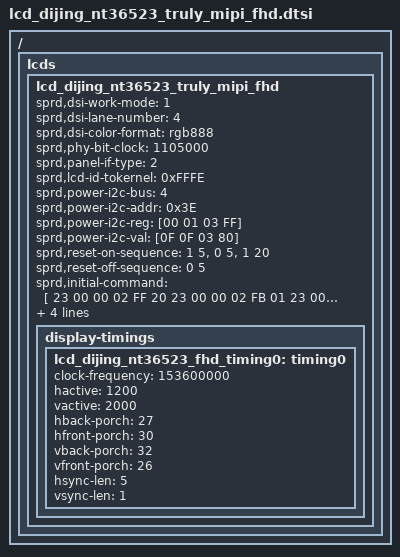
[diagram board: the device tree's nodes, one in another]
/*
 * dijing_2A4N3 Truly LCD config dtsi file for spreadtrum
 *
 * Copyright (C) 2018, Spreadtrum Communications Inc.
 *
 * SPDX-License-Identifier: (GPL-2.0+ OR MIT)
 */

/ { lcds {
	lcd_dijing_nt36523_truly_mipi_fhd: lcd_dijing_nt36523_truly_mipi_fhd {

					sprd,dsi-work-mode = <1>; /* video burst mode*/
					sprd,dsi-lane-number = <4>;
					sprd,dsi-color-format = "rgb888";

					sprd,phy-bit-clock = <1105000>;	/* 1062000~1075000 kbps 1068000 */

		/* panel interface type: 2:MIPI; 3:SPI */
		sprd,panel-if-type = <2>;

		/*----Id register ----*/
	//	sprd,lcd-id-register = [DA DB DC];
	//	sprd,lcd-id-value-len = <1 1 1>;
	//	sprd,lcd-id-value = [00 80 00];
		sprd,lcd-id-tokernel = <0xFFFE>;

		/*---Bias Power---*/
		sprd,power-i2c-bus = <4>;
		sprd,power-i2c-addr = <0x3E>;
		/*sprd,power-i2c-speed = <400000>;*/
		sprd,power-i2c-reg = [00 01 03 FF];
		sprd,power-i2c-val = [0F 0F 03 80];
		sprd,reset-on-sequence = <1 5>, <0 5>, <1 20>;
		sprd,reset-off-sequence = <0 5>;

		sprd,initial-command = [
				23 00 00 02 FF 20
				23 00 00 02 FB 01
				23 00 00 02 05 B1
				23 00 00 02 06 C0
				23 00 00 02 07 73
				23 00 00 02 08 4B
				23 00 00 02 0D 23
				23 00 00 02 0E 89
				23 00 00 02 0F 69
			//	23 00 00 02 88 00
			//	23 00 00 02 89 59
				23 00 00 02 94 00
				23 00 00 02 95 C3
                                23 00 00 02 96 C3
				23 00 00 02 09 99
				23 00 00 02 0A 88
				23 00 00 02 0B 10
				23 00 00 02 0C 00
				23 00 00 02 10 0C
				23 00 00 02 33 11
				23 00 00 02 58 60
				23 00 00 02 60 88
				23 00 00 02 30 10
				23 00 00 02 31 02
				23 00 00 02 32 B2
				//Chopper
				23 00 00 02 75 A2
				23 00 00 02 77 66
				
				//GAMMA
				23 00 00 02 FF 20
				23 00 00 02 FB 01
				//R(+)
				39 00 00 11 B0 00 08 00 28 00 57 00 7B 00 99 00 B2 00 C8 00 DC
				39 00 00 11 B1 00 EC 01 26 01 4C 01 8B 01 B6 01 FA 02 2B 02 2D
				39 00 00 11 B2 02 5E 02 98 02 C8 02 FE 03 28 03 56 03 68 03 78
				39 00 00 0D B3 03 8B 03 A0 03 B5 03 E4 03 FD 03 FF
				//G(+)
				39 00 00 11 B4 00 08 00 28 00 57 00 7B 00 99 00 B2 00 C8 00 DC
				39 00 00 11 B5 00 EC 01 26 01 4C 01 8B 01 B6 01 FA 02 2B 02 2D
				39 00 00 11 B6 02 5E 02 98 02 C8 02 FE 03 28 03 56 03 68 03 78
				39 00 00 0D B7 03 8B 03 A0 03 B5 03 E4 03 FD 03 FF
				//B(+)
				39 00 00 11 B8 00 08 00 28 00 57 00 7B 00 99 00 B2 00 C8 00 DC
				39 00 00 11 B9 00 EC 01 26 01 4C 01 8B 01 B6 01 FA 02 2B 02 2D
				39 00 00 11 BA 02 5E 02 98 02 C8 02 FE 03 28 03 56 03 68 03 78
				39 00 00 0D BB 03 8B 03 A0 03 B5 03 E4 03 FD 03 FF
				
				23 00 00 02 FF 21
				23 00 00 02 FB 01
				//R(-)
				39 00 00 11 B0 00 00 00 20 00 4F 00 73 00 91 00 AA 00 C0 00 D4
				39 00 00 11 B1 00 E4 01 1E 01 44 01 83 01 AE 01 F2 02 23 02 25
				39 00 00 11 B2 02 56 02 90 02 C0 02 F6 03 20 03 4E 03 60 03 70
				39 00 00 0D B3 03 83 03 98 03 AD 03 DC 03 F5 03 F7
				//G(-)
				39 00 00 11 B4 00 00 00 20 00 4F 00 73 00 91 00 AA 00 C0 00 D4
				39 00 00 11 B5 00 E4 01 1E 01 44 01 83 01 AE 01 F2 02 23 02 25
				39 00 00 11 B6 02 56 02 90 02 C0 02 F6 03 20 03 4E 03 60 03 70
				39 00 00 0D B7 03 83 03 98 03 AD 03 DC 03 F5 03 F7
				//B(-)
				39 00 00 11 B8 00 00 00 20 00 4F 00 73 00 91 00 AA 00 C0 00 D4
				39 00 00 11 B9 00 E4 01 1E 01 44 01 83 01 AE 01 F2 02 23 02 25
				39 00 00 11 BA 02 56 02 90 02 C0 02 F6 03 20 03 4E 03 60 03 70
				39 00 00 0D BB 03 83 03 98 03 AD 03 DC 03 F5 03 F7
				
				23 00 00 02 FF 23
				23 00 00 02 FB 01
				23 00 00 02 00 80
				23 00 00 02 07 00
				23 00 00 02 08 01
				23 00 00 02 09 2C
				23 00 00 02 11 01
				23 00 00 02 12 77
				23 00 00 02 15 07
				23 00 00 02 16 07
				
				23 00 00 02 FF 24
				23 00 00 02 FB 01
				23 00 00 02 60 96
				23 00 00 02 61 D0
				23 00 00 02 63 70
				23 00 00 02 91 00
				23 00 00 02 92 D4
				23 00 00 02 93 1A
				23 00 00 02 94 08
				23 00 00 02 C2 CA
				23 00 00 02 00 29
				23 00 00 02 01 08
				23 00 00 02 02 28
				23 00 00 02 03 03
				23 00 00 02 04 04
				23 00 00 02 05 13
				23 00 00 02 06 12
				23 00 00 02 07 11
				23 00 00 02 08 10
				23 00 00 02 09 0F
				23 00 00 02 0A 0E
				23 00 00 02 0B 0D
				23 00 00 02 0C 0C
				23 00 00 02 0D 27
				23 00 00 02 0E 03
				23 00 00 02 0F 03
				23 00 00 02 10 03
				23 00 00 02 11 03
				23 00 00 02 12 03
				23 00 00 02 13 03
				23 00 00 02 14 03
				23 00 00 02 15 03
				23 00 00 02 16 29
				23 00 00 02 17 08
				23 00 00 02 18 28
				23 00 00 02 19 03
				23 00 00 02 1A 04
				23 00 00 02 1B 13
				23 00 00 02 1C 12
				23 00 00 02 1D 11
				23 00 00 02 1E 10
				23 00 00 02 1F 0F
				23 00 00 02 20 0E
				23 00 00 02 21 0D
				23 00 00 02 22 0C
				23 00 00 02 23 27
				23 00 00 02 24 03
				23 00 00 02 25 03
				23 00 00 02 26 03
				23 00 00 02 27 03
				23 00 00 02 28 03
				23 00 00 02 29 03
				23 00 00 02 2A 03
				23 00 00 02 2B 03
				23 00 00 02 2F 06
				23 00 00 02 33 06
				23 00 00 02 37 44
				23 00 00 02 3A 02
				23 00 00 02 3B 98
				23 00 00 02 3D 81
				23 00 00 02 AB 44
				23 00 00 02 3F 5B
				23 00 00 02 43 5B
				23 00 00 02 47 44
				23 00 00 02 4A 02
				23 00 00 02 4B 68
				23 00 00 02 4C 01
				23 00 00 02 F7 44
				23 00 00 02 4D 21                                                                                                                         
				23 00 00 02 4E 43                                                                                                                          
				23 00 00 02 4F 65                                                                                                                          
				23 00 00 02 50 87                                                                                                                          
				23 00 00 02 51 78                                                                                                                          
				23 00 00 02 52 56                                                                                                                          
				23 00 00 02 53 34                                                                                                                          
				23 00 00 02 54 12                                                                                                                          
				39 00 00 03 55 85 05                                                                                                                     
				23 00 00 02 56 08                                                                                                                          
				23 00 00 02 58 10                                                                                                                          
				23 00 00 02 59 20                                                                                                                          
				23 00 00 02 5A A0                                                                                                                          
				23 00 00 02 5B 98                                                                                                                          
				23 00 00 02 5C 00                                                                                                                          
				23 00 00 02 5D 00                                                                                                                          
				39 00 00 03 5E 00 04                                                                                                                       
				23 00 00 02 5F 00                                                                                                                          
				23 00 00 02 98 80                                                                                                                          
				23 00 00 02 AA 03                                                                                                                          
				23 00 00 02 D7 55                                                                                                                          
				23 00 00 02 D8 55                                                                                                                          
				23 00 00 02 D9 23                                                                                                                          
				23 00 00 02 DA 05                                                                                                                          
				23 00 00 02 DB 72                                                                                                                          
				23 00 00 02 DC D0                                                                                                                          
				23 00 00 02 DD 55                                                                                                                          
				23 00 00 02 DE 27                                                                                                                          
				23 00 00 02 DF 02                                                                                                                          
				23 00 00 02 E0 D0                                                                                                                          
				23 00 00 02 E1 02                                                                                                                          
				23 00 00 02 E2 D0                                                                                                                          
				23 00 00 02 E3 02                                                                                                                          
				23 00 00 02 E4 D0                                                                                                                          
				23 00 00 02 E5 02                                                                                                                          
				23 00 00 02 E6 D0                                                                                                                          
				23 00 00 02 E7 00                                                                                                                          
				23 00 00 02 E8 00                                                                                                                          
				23 00 00 02 E9 02                                                                                                                          
				23 00 00 02 EA D0                                                                                                                          
				23 00 00 02 EB 02                                                                                                                          
				23 00 00 02 EE D0                                                                                                                          
				23 00 00 02 EF 02                                                                                                                          
				23 00 00 02 F0 D0
				39 00 00 0D B6 05 00 05 00 00 00 00 00 05 05 00 00
				
				23 00 00 02 FF 25				
				23 00 00 02 FB 01                                                                                                                          
				23 00 00 02 05 00                                                                                                                          
				23 00 00 02 13 03                                                                                                                          
				23 00 00 02 14 12                                                                                                                          
				23 00 00 02 19 07                                                                                                                          
				23 00 00 02 1B 11                                                                                                                          
				23 00 00 02 1E 00                                                                                                                          
				23 00 00 02 1F A0                                                                                                                          
				23 00 00 02 20 98                                                                                                                          
				23 00 00 02 25 00                                                                                                                          
				23 00 00 02 26 A0                                                                                                                          
				23 00 00 02 27 98                                                                                                                          
				23 00 00 02 3F 00                                                                                                                          
				23 00 00 02 40 03                                                                                                                          
				23 00 00 02 43 00                                                                                                                          
				23 00 00 02 48 A0                                                                                                                          
				23 00 00 02 49 98                                                                                                                          
				23 00 00 02 44 02                                                                                                                          
				23 00 00 02 45 98                                                                                                                          
				23 00 00 02 46 02                                                                                                                          
				23 00 00 02 47 98                                                                                                                          
				23 00 00 02 5D 02                                                                                                                          
				23 00 00 02 5E 98                                                                                                                          
				23 00 00 02 5F 02                                                                                                                          
				23 00 00 02 60 98                                                                                                                          
				23 00 00 02 61 A0                                                                                                                          
				23 00 00 02 62 98                                                                                                                          
				23 00 00 02 6B 40                                                                                                                          
				23 00 00 02 6C 0D                                                                                                                          
				23 00 00 02 6D 0D                                                                                                                          
				23 00 00 02 6E 0E                                                                                                                          
				23 00 00 02 6F 0E                                                                                                                          
				23 00 00 02 78 00                                                                                                                          
				23 00 00 02 79 DA                                                                                                                          
				23 00 00 02 7A 00                                                                                                                          
				23 00 00 02 7B 68                                                                                                                          
				23 00 00 02 86 01                                                                                                                          
				23 00 00 02 87 0A                                                                                                                          
				23 00 00 02 88 1A                                                                                                                          
				23 00 00 02 C0 0C 
				
				23 00 00 02 FF 26			
				23 00 00 02 FB 01                                                                                                                          
				23 00 00 02 00 A1                                                                                                                          
				23 00 00 02 04 28                                                                                                                          
				23 00 00 02 06 30                                                                                                                          
				23 00 00 02 0C 11                                                                                                                          
				23 00 00 02 0D 00                                                                                                                          
				23 00 00 02 0F 09                                                                                                                          
				23 00 00 02 11 12                                                                                                                          
				23 00 00 02 12 50                                                                                                                          
				23 00 00 02 13 6D                                                                                                                          
				23 00 00 02 14 93                                                                                                                          
				23 00 00 02 15 00                                                                                                                          
				23 00 00 02 16 90                                                                                                                          
				23 00 00 02 17 A0                                                                                                                          
				23 00 00 02 18 86                                                                                                                          
				23 00 00 02 19 11                                                                                                                          
				23 00 00 02 1A 00                                                                                                                          
				23 00 00 02 1B 0E                                                                                                                          
				23 00 00 02 1C DC                                                                                                                          
				23 00 00 02 22 00                                                                                                                          
				23 00 00 02 23 00                                                                                                                          
				23 00 00 02 2A 11                                                                                                                          
				23 00 00 02 2B 00                                                                                                                          
				23 00 00 02 1D 00                                                                                                                          
				23 00 00 02 1E D4                                                                                                                          
				23 00 00 02 1F D4                                                                                                                          
				23 00 00 02 20 00                                                                                                                          
				23 00 00 02 21 07                                                                                                                          
				23 00 00 02 2F 03                                                                                                                          
				23 00 00 02 30 D4                                                                                                                          
				23 00 00 02 33 78                                                                                                                          
				23 00 00 02 34 16                                                                                                                          
				23 00 00 02 35 11                                                                                                                          
				23 00 00 02 39 04                                                                                                                          
				23 00 00 02 3A D4                                                                                                                          
				23 00 00 02 3B 06                                                                                                                          
				23 00 00 02 3F 00                                                                                                                          
				23 00 00 02 40 C8                                                                                                                          
				23 00 00 02 41 C8                                                                                                                          
				23 00 00 02 42 C8                                                                                                                          
				23 00 00 02 43 01                                                                                                                          
				23 00 00 02 44 C8                                                                                                                          
				23 00 00 02 45 05                                                                                                                          
				23 00 00 02 46 C8                                                                                                                          
				23 00 00 02 47 00                                                                                                                          
				23 00 00 02 48 C8                                                                                                                          
				23 00 00 02 49 05                                                                                                                          
				23 00 00 02 4A C8                                                                                                                          
				23 00 00 02 4B 80                                                                                                                          
				23 00 00 02 8B 28                                                                                                                          
				23 00 00 02 8C 00                                                                                                                          
				23 00 00 02 8D 01                                                                                                                          
				23 00 00 02 8F 01                                                                                                                          
				23 00 00 02 91 00                                                                                                                          
				23 00 00 02 92 50                                                                                                                          
				23 00 00 02 93 00                                                                                                                          
				23 00 00 02 94 00                                                                                                                          
				23 00 00 02 95 00                                                                                                                          
				23 00 00 02 96 00                                                                                                                          
				23 00 00 02 97 A0                                                                                                                          
				23 00 00 02 98 86                                                                                                                          
				23 00 00 02 99 0F                                                                                                                          
				23 00 00 02 9A 9C                                                                                                                          
				23 00 00 02 9B 0E                                                                                                                          
				23 00 00 02 9C DC                                                                                                                          
				23 00 00 02 9D 0F                                                                                                                          
				23 00 00 02 9E 9C                                                                                                                          
				23 00 00 02 9F 00                                                                                                                          
				23 00 00 02 A0 00                                                                                                                          
				23 00 00 02 C8 04                                                                                                                          
				23 00 00 02 C9 12                                                                                                                          
				23 00 00 02 CA 4E                                                                                                                          
				23 00 00 02 CB 00                                                                                                                          
				23 00 00 02 A9 79                                                                                                                          
				23 00 00 02 AA 7F                                                                                                                          
				23 00 00 02 AB 85                                                                                                                          
				23 00 00 02 AC 8B                                                                                                                          
				23 00 00 02 AD 91                                                                                                                          
				23 00 00 02 AE 97                                                                                                                          
				23 00 00 02 AF 9D                                                                                                                          
				23 00 00 02 B0 A3                                                                                                                          
				23 00 00 02 B1 A9                                                                                                                          
				23 00 00 02 B2 AF                                                                                                                          
				23 00 00 02 B3 B5                                                                                                                          
				23 00 00 02 B4 BB                                                                                                                          
				23 00 00 02 B5 C1                                                                                                                          
				23 00 00 02 B6 C7                                                                                                                          
				23 00 00 02 B7 CD                                                                                                                          
				23 00 00 02 B8 D3                                                                                                                          
				23 00 00 02 B9 D9 
				
				23 00 00 02 FF 27
				23 00 00 02 FB 01
				23 00 00 02 00 00
				23 00 00 02 C3 00
				23 00 00 02 58 00
				23 00 00 02 78 00
				
				23 00 00 02 FF 2A
				23 00 00 02 FB 01                                                                                                                          
				23 00 00 02 64 86                                                                                                                          
				23 00 00 02 67 86                                                                                                                          
				23 00 00 02 68 03                                                                                                                          
				23 00 00 02 6A 86                                                                                                                          
				23 00 00 02 82 86                                                                                                                          
				23 00 00 02 85 86                                                                                                                          
				23 00 00 02 88 86                                                                                                                          
				23 00 00 02 89 03                                                                                                                          
				23 00 00 02 97 3C                                                                                                                          
				23 00 00 02 98 02                                                                                                                          
				23 00 00 02 99 95                                                                                                                          
				23 00 00 02 9A 06                                                                                                                          
				23 00 00 02 9B 00                                                                                                                          
				23 00 00 02 9C 0B                                                                                                                          
				23 00 00 02 9D 0A                                                                                                                          
				23 00 00 02 9E 90                                                                                                                          
				23 00 00 02 A2 3F                                                                                                                          
				23 00 00 02 A3 00                                                                                                                          
				23 00 00 02 A4 3C                                                                                                                          
				23 00 00 02 A5 03                                                                                                                          
				23 00 00 02 22 00                                                                                                                          
				23 00 00 02 23 08                                                                                                                          
				23 00 00 02 24 00                                                                                                                          
				23 00 00 02 25 D8                                                                                                                          
				23 00 00 02 26 F8                                                                                                                          
				23 00 00 02 27 00                                                                                                                          
				23 00 00 02 28 1A                                                                                                                          
				23 00 00 02 29 00                                                                                                                          
				23 00 00 02 2A 1A                                                                                                                          
				23 00 00 02 2B 00                                                                                                                          
				23 00 00 02 2D 1A                                                                                                                          
				23 00 00 02 E8 00
				
				23 00 00 02 FF F0
				23 00 00 02 FB 01
				23 00 00 02 3A 08
				
                                23 00 00 02 FF 10
				23 00 00 02 B9 01
				23 00 00 02 FF 20		
				23 00 00 02 18 40
				
				23 00 00 02 FF 10
				23 00 00 02 B9 02
				23 00 00 02 FF 10			
				23 00 00 02 FB 01
				23 00 00 02 35 00
				23 00 00 02 BB 13
				39 00 00 06 3B 03 21 1A 04 04
				23 00 00 02 36 03			
				23 00 00 02 53 2C 
                                39 00 00 03 68 02 01 
                                
		//		23 00 00 02 FF 25 
		//		23 00 00 02 FB 01 
		//		23 00 00 02 EC 01 
				23 78 00 02 11 00
				23 14 00 02 29 00
			];

		sprd,sleep-in-command = [
			13 01 00 01 00
			13 0A 00 01 28
			13 78 00 01 10
			/*23 0a 00 02 4F 01*/
			];

		sprd,sleep-out-command = [
			13 50 00 01 11
			13 14 00 01 29
			];

		display-timings {
			lcd_dijing_nt36523_fhd_timing0: timing0 {
				clock-frequency = <153600000>;
							hactive = <1200>;
							vactive = <2000>;
							hback-porch = <27>;
							hfront-porch = <30>;
							vback-porch = <32>;
							vfront-porch = <26>;
							hsync-len = <5>;
							vsync-len = <1>;
			};
		};
	};
};};
